# AVR32LA32 register map
Vendor: Atmel; File version: 1.0
CPU: other r0p0, little endian, no MPU, no FPU, 4 interrupt priority bits
Registers are 8-bit, read-write, reset 0x0 unless marked. A register's access mark holds for its fields unless they carry their own. Offsets are from the block's base; lines under a group give offsets from that group; [hi:lo] are bit positions; {n}, {i} and the like mark numbered series; 'fields as' and 'values as' point back to an identical list; <NAME> marks a mode.

## Memory map
0x00800000 VPORTA size 0x4 — Virtual Ports
0x00800008 VPORTC size 0x4 — Virtual Ports
0x0080000C VPORTD size 0x4 — Virtual Ports
0x00800014 VPORTF size 0x4 — Virtual Ports
0x0080001C GPR size 0x4 — General Purpose Registers
0x00800030 CPU blocks up to offset 0x10
0x00800040 RSTCTRL size 0x2 — Reset controller
0x00800050 SLPCTRL size 0x1 — Sleep Controller
0x00800060 CLKCTRL blocks up to offset 0x1D — Clock controller
0x008000A0 BOD blocks up to offset 0xC — Bod interface
0x008000B4 VREF size 0x1 — Voltage reference
0x00800100 WDT size 0x2 — Watch-Dog Timer
0x00800110 CPUINT size 0x4 — Interrupt Controller
0x00800120 CRCSCAN blocks up to offset 0xC
0x00800140 RTC blocks up to offset 0x17 — Real-Time Counter
0x008001C0 CCL blocks up to offset 0x18 — Configurable Custom Logic
0x00800200 EVSYS blocks up to offset 0x31 — Event System
0x00800400 PORTA blocks up to offset 0x19 — I/O Ports
0x00800440 PORTC blocks up to offset 0x19 — I/O Ports
0x00800460 PORTD blocks up to offset 0x19 — I/O Ports
0x008004A0 PORTF blocks up to offset 0x19 — I/O Ports
0x008005E0 PORTMUX blocks up to offset 0xB — Port Multiplexer
0x00800600 ADC0 size 0x15 — Analog to Digital Converter
0x00800680 AC0 size 0x7 — Analog Comparator
0x00800800 USART0 blocks up to offset 0x20 — Universal Synchronous and Asynchronous Receiver and Transmitter
0x00800900 TWI0 size 0xF — Two-Wire Interface
0x00800940 SPI0 size 0x5 — Serial Peripheral Interface
0x00800A00 TCE0 blocks up to offset 0x3E — 16-bit Timer/Counter Type E
0x00800B00 TCB0 blocks up to offset 0xE — 16-bit Timer/Counter Type B
0x00800B10 TCB1 blocks up to offset 0xE — 16-bit Timer/Counter Type B
0x00800F01 SYSCFG blocks up to offset 0x7 — System Configuration Registers
0x00801000 NVMCTRL blocks up to offset 0x10 — Non-volatile Memory Controller
0x00801040 LOCK size 0x4 — Lockbits
0x00801080 SIGROW blocks up to offset 0x20 — Signature row
0x00801100 BOOTROW size 0x1
0x00801200 USERROW size 0x1

## Interrupts
1 CPU CRCSCAN_NMI (CPU)
2 BOD_VLM (CPU)
3 CRCSCAN_INT (CPU)
4 RTC_CNT (CPU)
5 RTC_PIT (CPU)
6 CCL_CCL (CPU)
7 PORTA_PORT (CPU)
8 TCE0_OVF (CPU)
9 TCE0_CMP0 (CPU)
10 TCE0_CMP1 (CPU)
11 TCE0_CMP2 (CPU)
12 TCB0_INT (CPU)
13 TCB1_INT (CPU)
14 TWI0_TWIS (CPU)
15 TWI0_TWIM (CPU)
16 SPI0_INT (CPU)
17 USART0_ERROR (CPU)
18 USART0_RXC (CPU)
19 USART0_DRE (CPU)
20 USART0_TXC (CPU)
21 PORTD_PORT (CPU)
22 AC0_INT (CPU)
23 ADC0_ERROR (CPU)
24 ADC0_RESRDY (CPU)
25 ADC0_SAMPRDY (CPU)
26 PORTC_PORT (CPU)
27 PORTF_PORT (CPU)
28 NVMCTRL_NVMREADY (CPU)

## AC0 — Analog Comparator
Base 0x00800680
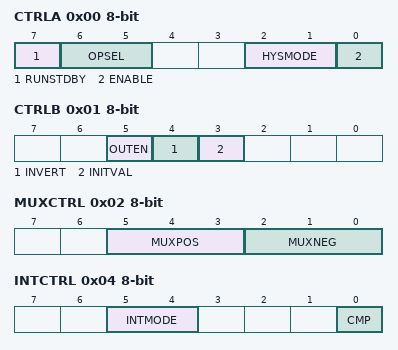
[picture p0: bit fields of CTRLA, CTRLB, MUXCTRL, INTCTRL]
0x00 CTRLA — Control A
  [7] RUNSTDBY — Run in Standby Mode
  [6:5] OPSEL — Operation Select
    0=CONT (Continuous mode); 1=EVENT (Event triggered mode); 2=SAMP1K (Sampled mode, 1 kHz sampling frequency); 3=SAMP128 (Sampled mode, 128 Hz sampling frequency)
  [2:1] HYSMODE — Hysteresis Mode Select
    0=NONE (No hysteresis); 1=SMALL (Small hysteresis); 2=MEDIUM (Medium hysteresis); 3=LARGE (Large hysteresis)
  [0] ENABLE — Enable AC
0x01 CTRLB — Control B
  [5] OUTEN — Output Enable
  [4] INVERT — Invert AC Output
  [3] INITVAL — Output initial value
    0=LOW (Output initialized to 0); 1=HIGH (Output initialized to 1)
0x02 MUXCTRL — Multiplexer Control
  [5:3] MUXPOS — Positive Input MUX Selection
    0=AINP0 (Positive Pin 0); 3=AINP3 (Positive Pin 3); 7=VDDDIV10 (VDD divided by 10)
  [2:0] MUXNEG — Negative Input MUX Selection
    0=AINN0 (Negative Pin 0); 1=AINN1 (Negative Pin 1); 2=AINN2 (Negative Pin 2); 4=REFSCALE (Reference Scaler)
0x03 REFSCALE — Reference Scaling
  [7:0] REFSCALE — Scaled Reference Voltage
0x04 INTCTRL — Interrupt Control
  [5:4] INTMODE — Interrupt Mode
    0=BOTHEDGE (Positive and negative inputs crosses); 2=NEGEDGE (Positive input goes below negative input); 3=POSEDGE (Positive input goes above negative input)
  [0] CMP — Comparator Interrupt Enable
0x05 INTFLAGS — Interrupt Flags
  [0] CMP — Comparator Interrupt Flag
0x06 STATUS ro
  [0] CMP — Analog Comparator State
    0=LOW (Comparator output is low); 1=HIGH (Comparator output is high)
